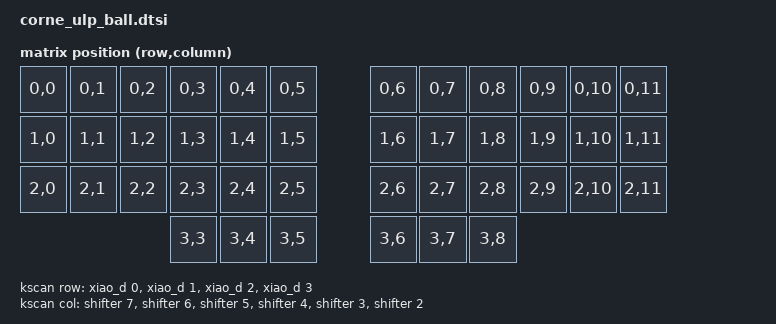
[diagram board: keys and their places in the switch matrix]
// This file was generated from a template. Edit it to match your keyboard.
// See https://zmk.dev/docs/development/hardware-integration/new-shield for more
// instructions.

#include <dt-bindings/zmk/matrix_transform.h>

#include "corne_ulp_ball-layouts.dtsi"

/ {
    chosen {
        zmk,physical-layout = &default_layout;
    };

    kscan: kscan {
        // If the hardware does not use a switch matrix, change this to the
        // appropriate driver and update the properties below to match.
        // See https://zmk.dev/docs/config/kscan for supported key scan drivers.
        compatible = "zmk,kscan-gpio-matrix";
        // Set this to "col2row" or "row2col" to match the hardware. If using
        // "row2col", change the col-gpios in the _left.overlay and _right.overlay
        // files to (GPIO_ACTIVE_HIGH | GPIO_PULL_DOWN) and the row-gpios here to
        // GPIO_ACTIVE_HIGH.
        diode-direction = "col2row";
        wakeup-source;

        // Replace these comments with the GPIO pins in the matrix.
        // See https://zmk.dev/docs/development/hardware-integration/new-shield#shield-overlays
        row-gpios
            = <&xiao_d 0 (GPIO_ACTIVE_HIGH | GPIO_PULL_DOWN)>
            , <&xiao_d 1 (GPIO_ACTIVE_HIGH | GPIO_PULL_DOWN)>
            , <&xiao_d 2 (GPIO_ACTIVE_HIGH | GPIO_PULL_DOWN)>
            , <&xiao_d 3 (GPIO_ACTIVE_HIGH | GPIO_PULL_DOWN)>
            ;

        col-gpios
            = <&shifter 7 GPIO_ACTIVE_HIGH>
            , <&shifter 6 GPIO_ACTIVE_HIGH>
            , <&shifter 5 GPIO_ACTIVE_HIGH>
            , <&shifter 4 GPIO_ACTIVE_HIGH>
            , <&shifter 3 GPIO_ACTIVE_HIGH>
            , <&shifter 2 GPIO_ACTIVE_HIGH>
            ;

    };

    default_transform: default_transform {
        // See https://zmk.dev/docs/development/hardware-integration/new-shield#matrix-transform
        // for how to configure this
        compatible = "zmk,matrix-transform";
        columns = <12>;
        rows = <4>;

        map = <
            RC(0, 0) RC(0, 1) RC(0, 2) RC(0, 3) RC(0, 4) RC(0, 5)    RC(0, 6) RC(0, 7) RC(0, 8) RC(0, 9) RC(0,10) RC(0,11)
            RC(1, 0) RC(1, 1) RC(1, 2) RC(1, 3) RC(1, 4) RC(1, 5)    RC(1, 6) RC(1, 7) RC(1, 8) RC(1, 9) RC(1,10) RC(1,11)
            RC(2, 0) RC(2, 1) RC(2, 2) RC(2, 3) RC(2, 4) RC(2, 5)    RC(2, 6) RC(2, 7) RC(2, 8) RC(2, 9) RC(2,10) RC(2,11)
                                       RC(3, 3) RC(3, 4) RC(3, 5)    RC(3, 6) RC(3, 7) RC(3, 8)
        >;
    };

    split_inputs {
        #address-cells = <1>;
        #size-cells = <0>;

        trackball_split: trackball_split@0 {
            compatible = "zmk,input-split";
            reg = <0>;
        };

        trackball_split: trackball_split@1 {
            compatible = "zmk,input-split";
            reg = <1>;
        };
    };

    trackball_input_listener_0: trackball_input_listener_0 {
        compatible = "zmk,input-listener";
        status = "disabled";
        device = <&trackball_split>;
    };

    trackball_input_listener_1: trackball_input_listener_1 {
        compatible = "zmk,input-listener";
        status = "disabled";
        device = <&trackball_split>;
    };
};

&xiao_spi {
    status = "okay";
    cs-gpios = <&xiao_d 9 GPIO_ACTIVE_LOW>;
    shifter: 595@0 {
        compatible = "zmk,gpio-595";
        status = "okay";
        gpio-controller;
        spi-max-frequency = <200000>;
        reg = <0>;
        #gpio-cells = <2>;
        ngpios = <8>;
    };
};
